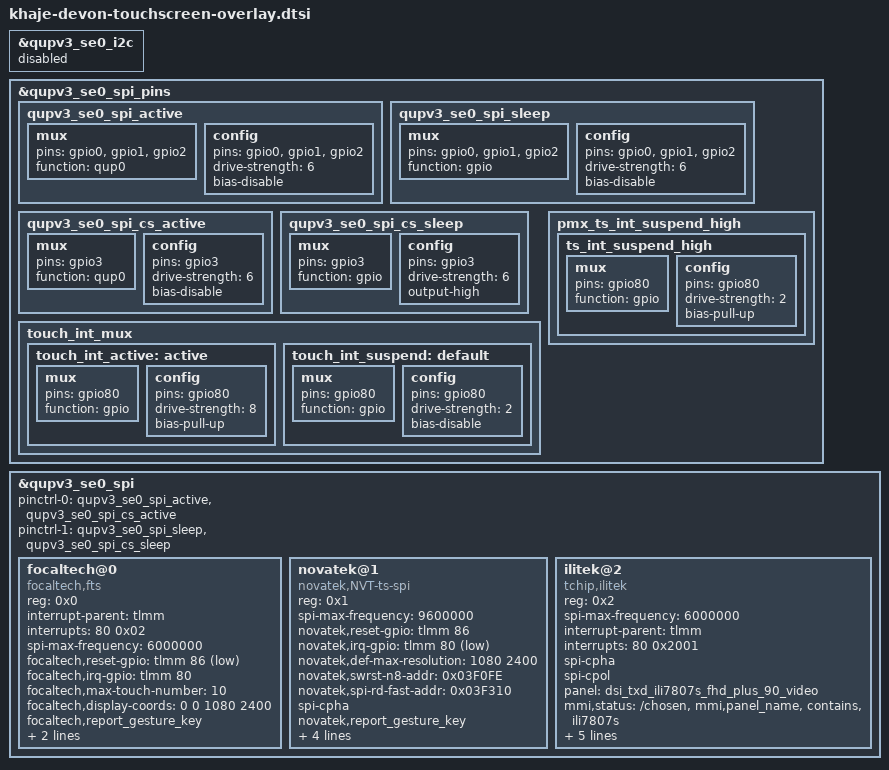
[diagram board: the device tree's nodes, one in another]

&qupv3_se0_i2c {
	status = "disabled";
};

&qupv3_se0_spi_pins {
	qupv3_se0_spi_active: qupv3_se0_spi_active {
		mux {
			pins = "gpio0", "gpio1", "gpio2";
			function = "qup0";
		};

		config {
			pins = "gpio0", "gpio1", "gpio2";
			drive-strength = <6>;
			bias-disable;
		};
	};

	qupv3_se0_spi_sleep: qupv3_se0_spi_sleep {
		mux {
			pins = "gpio0", "gpio1", "gpio2";
			function = "gpio";
		};

		config {
			pins = "gpio0", "gpio1", "gpio2";
			drive-strength = <6>;
			bias-disable;
		};
	};

	qupv3_se0_spi_cs_active: qupv3_se0_spi_cs_active {
		mux {
			pins = "gpio3";
			function = "qup0";
		};

		config {
			pins = "gpio3";
			drive-strength = <6>;
			bias-disable;
		};
	};

	qupv3_se0_spi_cs_sleep: qupv3_se0_spi_cs_sleep {
		mux {
			pins = "gpio3";
			function = "gpio";
		};

		config {
			pins = "gpio3";
			drive-strength = <6>;
			output-high;
		};
	};
	touch_int_mux {
		touch_int_active: active {
			mux {
				pins = "gpio80";
				function = "gpio";
			};
			config {
				pins = "gpio80";
				drive-strength = <8>;
				bias-pull-up;
			};
		};

		touch_int_suspend: default {
			mux {
				pins = "gpio80";
				function = "gpio";
			};
			config {
				pins = "gpio80";
				drive-strength = <2>;
				bias-disable;
			};
		};
	};

	pmx_ts_int_suspend_high {
		ts_int_suspend_high: ts_int_suspend_high {
			mux {
				pins = "gpio80";
				function = "gpio";
			};
			config {
				pins = "gpio80";
				drive-strength = <2>;
				bias-pull-up;
			};
		};
	};
};

&qupv3_se0_spi {
	status = "ok";
	pinctrl-0 = <&qupv3_se0_spi_active &qupv3_se0_spi_cs_active>;
	pinctrl-1 = <&qupv3_se0_spi_sleep &qupv3_se0_spi_cs_sleep>;

	focaltech@0{
		compatible = "focaltech,fts";
		reg = <0x0>;
		interrupt-parent = <&tlmm>;
		interrupts = <80 0x02>;
		spi-max-frequency = <6000000>;
		focaltech,reset-gpio = <&tlmm 86 0x01>;
		focaltech,irq-gpio = <&tlmm 80 0x02>;
		focaltech,max-touch-number = <10>;
		focaltech,display-coords =  <0 0 1080 2400>;
		focaltech,report_gesture_key;
		focaltech,panel-supplier = "txd";
		panel = <&dsi_ft8726_txd_90hz_video>;
        };

	novatek@1{
		compatible = "novatek,NVT-ts-spi";
		reg = <0x1>;
		spi-max-frequency = <9600000>;  /* 4800000,9600000,15000000,19200000 */
		novatek,reset-gpio = <&tlmm 86 0x00>;
		novatek,irq-gpio = <&tlmm 80 0x2001>;
		novatek,def-max-resolution = <1080 2400>;
		novatek,swrst-n8-addr = <0x03F0FE>;
		novatek,spi-rd-fast-addr = <0x03F310>;
		spi-cpha;
		novatek,report_gesture_key;
		novatek,gesture-wait-pm;
		novatek,usb_charger;
		novatek,panel-supplier = "tm";
		panel = <&dsi_tm_nt36672c_fhd_plus_90_video>;
		status = "ok";
	};

	ilitek@2 {
		compatible = "tchip,ilitek";
		reg = <0x2>;
		spi-max-frequency = <6000000>;
		interrupt-parent = <&tlmm>;
		interrupts = <80 0x2001>;
		spi-cpha;
		spi-cpol;
		panel = <&dsi_txd_ili7807s_fhd_plus_90_video>;
		mmi,status = "/chosen","mmi,panel_name","contains","ili7807s";
		touch,reset-gpio = <&tlmm 86 0x00>;
		touch,irq-gpio = <&tlmm 80 0x2001>;
		pinctrl-names = "pmx_ts_int_active","pmx_ts_int_suspend_high";
		pinctrl-3 = <&ts_int_active>;
		pinctrl-4 = <&ts_int_suspend_high>;
		ilitek,report_gesture_key;
		status = "ok";
	};

};

